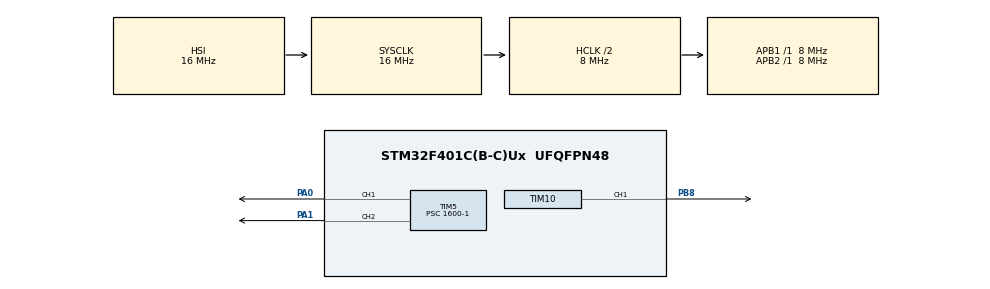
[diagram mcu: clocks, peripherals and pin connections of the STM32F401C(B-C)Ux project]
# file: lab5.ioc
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Mcu.Family=STM32F4
Mcu.Name=STM32F401C(B-C)Ux
Mcu.Package=UFQFPN48
NVIC.PriorityGroup=NVIC_PRIORITYGROUP_4
NVIC.TIM1_BRK_TIM9_IRQn=true\:0\:0\:false\:false\:true\:true\:true\:true
PA0-WKUP.Signal=S_TIM5_CH1
PA1.Signal=S_TIM5_CH2
PB8.Signal=S_TIM10_CH1
ProjectManager.HeapSize=0x200
ProjectManager.StackSize=0x400
ProjectManager.TargetToolchain=STM32CubeIDE
RCC.AHBCLKDivider=RCC_SYSCLK_DIV2
RCC.AHBFreq_Value=8000000
RCC.APB1Freq_Value=8000000
RCC.APB1TimFreq_Value=8000000
RCC.APB2Freq_Value=8000000
RCC.APB2TimFreq_Value=8000000
RCC.CortexFreq_Value=8000000
RCC.HCLKFreq_Value=8000000
RCC.HSE_VALUE=25000000
RCC.HSI_VALUE=16000000
RCC.LSE_VALUE=32768
RCC.SYSCLKFreq_VALUE=16000000
RCC.VCOOutputFreq_Value=192000000
SH.S_TIM10_CH1.0=TIM10_CH1,PWM Generation1 CH1
SH.S_TIM5_CH1.0=TIM5_CH1,PWM Generation1 CH1
SH.S_TIM5_CH2.0=TIM5_CH2,PWM Generation2 CH2
TIM10.Channel=TIM_CHANNEL_1
TIM10.Period=1000
TIM10.Prescaler=1000-1
TIM5.Channel-PWM\ Generation1\ CH1=TIM_CHANNEL_1
TIM5.Channel-PWM\ Generation2\ CH2=TIM_CHANNEL_2
TIM5.Period=100-1
TIM5.Prescaler=1600-1
TIM5.Pulse-PWM\ Generation1\ CH1=14
TIM5.Pulse-PWM\ Generation2\ CH2=24
TIM9.Period=1000-1
TIM9.Prescaler=8000-1
VP_TIM10_VS_ClockSourceINT.Mode=Enable_Timer
VP_TIM5_VS_ClockSourceINT.Mode=Internal
VP_TIM9_VS_ClockSourceINT.Mode=Internal
board=custom

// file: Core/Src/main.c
/* USER CODE BEGIN Header */
/**
 ******************************************************************************
 * @file           : main.c
 * @brief          : Main program body
 ******************************************************************************
 * @attention
 *
 * Copyright (c) 2022 STMicroelectronics.
 * All rights reserved.
 *
 * This software is licensed under terms that can be found in the LICENSE file
 * in the root directory of this software component.
 * If no LICENSE file comes with this software, it is provided AS-IS.
 *
 ******************************************************************************
 */
/* USER CODE END Header */
#include "main.h"

 TIM_HandleTypeDef htim5;
TIM_HandleTypeDef htim9;
TIM_HandleTypeDef htim10;

void SystemClock_Config(void);
static void MX_GPIO_Init(void);
static void MX_TIM9_Init(void);
static void MX_TIM10_Init(void);
static void MX_TIM5_Init(void);

int main(void)
{

  /* MCU Configuration--------------------------------------------------------*/

  /* Reset of all peripherals, Initializes the Flash interface and the Systick. */
  HAL_Init();

  /* Configure the system clock */
  SystemClock_Config();

  /* Initialize all configured peripherals */
  MX_GPIO_Init();
  MX_TIM9_Init();
  MX_TIM10_Init();
  MX_TIM5_Init();
  /* USER CODE BEGIN 2 */
  HAL_TIM_Base_Start_IT(&htim5);
  HAL_TIM_Base_Start_IT(&htim9);
  HAL_TIM_Base_Start_IT(&htim10);
  HAL_TIM_PWM_Start(&htim10, TIM_CHANNEL_1);
  HAL_TIM_PWM_Start(&htim5, TIM_CHANNEL_1);
  HAL_TIM_PWM_Start(&htim5, TIM_CHANNEL_2);
  /* USER CODE END 2 */

  /* Infinite loop */
	while (1) {

	}
}

void SystemClock_Config(void)
{
  RCC_OscInitTypeDef RCC_OscInitStruct = {0};
  RCC_ClkInitTypeDef RCC_ClkInitStruct = {0};

  /** Configure the main internal regulator output voltage
  */
  __HAL_RCC_PWR_CLK_ENABLE();
  __HAL_PWR_VOLTAGESCALING_CONFIG(PWR_REGULATOR_VOLTAGE_SCALE2);

  /** Initializes the RCC Oscillators according to the specified parameters
  * in the RCC_OscInitTypeDef structure.
  */
  RCC_OscInitStruct.OscillatorType = RCC_OSCILLATORTYPE_HSI;
  RCC_OscInitStruct.HSIState = RCC_HSI_ON;
  RCC_OscInitStruct.HSICalibrationValue = RCC_HSICALIBRATION_DEFAULT;
  RCC_OscInitStruct.PLL.PLLState = RCC_PLL_NONE;
  if (HAL_RCC_OscConfig(&RCC_OscInitStruct) != HAL_OK)
  {
    Error_Handler();
  }

  /** Initializes the CPU, AHB and APB buses clocks
  */
  RCC_ClkInitStruct.ClockType = RCC_CLOCKTYPE_HCLK|RCC_CLOCKTYPE_SYSCLK
                              |RCC_CLOCKTYPE_PCLK1|RCC_CLOCKTYPE_PCLK2;
  RCC_ClkInitStruct.SYSCLKSource = RCC_SYSCLKSOURCE_HSI;
  RCC_ClkInitStruct.AHBCLKDivider = RCC_SYSCLK_DIV2;
  RCC_ClkInitStruct.APB1CLKDivider = RCC_HCLK_DIV1;
  RCC_ClkInitStruct.APB2CLKDivider = RCC_HCLK_DIV1;

  if (HAL_RCC_ClockConfig(&RCC_ClkInitStruct, FLASH_LATENCY_0) != HAL_OK)
  {
    Error_Handler();
  }
}

static void MX_TIM5_Init(void)
{

  TIM_ClockConfigTypeDef sClockSourceConfig = {0};
  TIM_MasterConfigTypeDef sMasterConfig = {0};
  TIM_OC_InitTypeDef sConfigOC = {0};

  htim5.Instance = TIM5;
  htim5.Init.Prescaler = 1600-1;
  htim5.Init.CounterMode = TIM_COUNTERMODE_UP;
  htim5.Init.Period = 100-1;
  htim5.Init.ClockDivision = TIM_CLOCKDIVISION_DIV1;
  htim5.Init.AutoReloadPreload = TIM_AUTORELOAD_PRELOAD_DISABLE;
  if (HAL_TIM_Base_Init(&htim5) != HAL_OK)
  {
    Error_Handler();
  }
  sClockSourceConfig.ClockSource = TIM_CLOCKSOURCE_INTERNAL;
  if (HAL_TIM_ConfigClockSource(&htim5, &sClockSourceConfig) != HAL_OK)
  {
    Error_Handler();
  }
  if (HAL_TIM_PWM_Init(&htim5) != HAL_OK)
  {
    Error_Handler();
  }
  sMasterConfig.MasterOutputTrigger = TIM_TRGO_RESET;
  sMasterConfig.MasterSlaveMode = TIM_MASTERSLAVEMODE_DISABLE;
  if (HAL_TIMEx_MasterConfigSynchronization(&htim5, &sMasterConfig) != HAL_OK)
  {
    Error_Handler();
  }
  sConfigOC.OCMode = TIM_OCMODE_PWM1;
  sConfigOC.Pulse = 14;
  sConfigOC.OCPolarity = TIM_OCPOLARITY_HIGH;
  sConfigOC.OCFastMode = TIM_OCFAST_DISABLE;
  if (HAL_TIM_PWM_ConfigChannel(&htim5, &sConfigOC, TIM_CHANNEL_1) != HAL_OK)
  {
    Error_Handler();
  }
  sConfigOC.Pulse = 24;
  if (HAL_TIM_PWM_ConfigChannel(&htim5, &sConfigOC, TIM_CHANNEL_2) != HAL_OK)
  {
    Error_Handler();
  }
  HAL_TIM_MspPostInit(&htim5);

}

static void MX_TIM9_Init(void)
{

  TIM_ClockConfigTypeDef sClockSourceConfig = {0};

  htim9.Instance = TIM9;
  htim9.Init.Prescaler = 8000-1;
  htim9.Init.CounterMode = TIM_COUNTERMODE_UP;
  htim9.Init.Period = 1000-1;
  htim9.Init.ClockDivision = TIM_CLOCKDIVISION_DIV1;
  htim9.Init.AutoReloadPreload = TIM_AUTORELOAD_PRELOAD_DISABLE;
  if (HAL_TIM_Base_Init(&htim9) != HAL_OK)
  {
    Error_Handler();
  }
  sClockSourceConfig.ClockSource = TIM_CLOCKSOURCE_INTERNAL;
  if (HAL_TIM_ConfigClockSource(&htim9, &sClockSourceConfig) != HAL_OK)
  {
    Error_Handler();
  }

}

static void MX_TIM10_Init(void)
{

  TIM_OC_InitTypeDef sConfigOC = {0};

  htim10.Instance = TIM10;
  htim10.Init.Prescaler = 1000-1;
  htim10.Init.CounterMode = TIM_COUNTERMODE_UP;
  htim10.Init.Period = 1000;
  htim10.Init.ClockDivision = TIM_CLOCKDIVISION_DIV1;
  htim10.Init.AutoReloadPreload = TIM_AUTORELOAD_PRELOAD_DISABLE;
  if (HAL_TIM_Base_Init(&htim10) != HAL_OK)
  {
    Error_Handler();
  }
  if (HAL_TIM_PWM_Init(&htim10) != HAL_OK)
  {
    Error_Handler();
  }
  sConfigOC.OCMode = TIM_OCMODE_PWM1;
  sConfigOC.Pulse = 0;
  sConfigOC.OCPolarity = TIM_OCPOLARITY_HIGH;
  sConfigOC.OCFastMode = TIM_OCFAST_DISABLE;
  if (HAL_TIM_PWM_ConfigChannel(&htim10, &sConfigOC, TIM_CHANNEL_1) != HAL_OK)
  {
    Error_Handler();
  }
  HAL_TIM_MspPostInit(&htim10);

}

static void MX_GPIO_Init(void)
{

  /* GPIO Ports Clock Enable */
  __HAL_RCC_GPIOA_CLK_ENABLE();
  __HAL_RCC_GPIOB_CLK_ENABLE();

}

/* USER CODE BEGIN 4 */

static int temp = 0;
static int flag = 1;

void HAL_TIM_PeriodElapsedCallback(TIM_HandleTypeDef *htim) {

	if (htim->Instance == TIM9) {

		int inc = 100 * flag;
		temp += inc;
		if (temp > 1000 || temp < 0) {
			flag *= -1;
			temp -= inc;
		}
		__HAL_TIM_SetCompare(&htim10, TIM_CHANNEL_1, temp);

	}

}
/* USER CODE END 4 */

void Error_Handler(void)
{
	__disable_irq();
	while (1) {
	}
}
